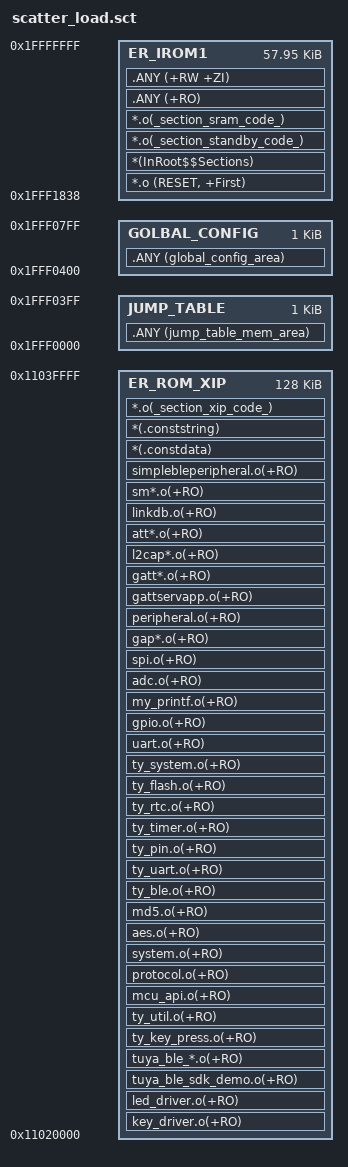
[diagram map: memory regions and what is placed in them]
; *************************************************************
; *** Scatter-Loading Description File generated by uVision ***
; *************************************************************

LR_IROM1 0x1fff1838 0x0E7C8 {  ; load region size_region
 ER_IROM1 0x1fff1838 0x0E7C8  {  ; load address = execution address
  *.o (RESET, +First)
  *(InRoot$$Sections)
  *.o(_section_standby_code_)
  *.o(_section_sram_code_)
  .ANY (+RO)  
  .ANY (+RW +ZI)
 }
;  ER_IROM2 0x1fffc000 0x04000  {  ; load address = execution address
;  rf_phy_driver.o(i.rf_phy_dtm*)
;  rf_phy_driver.o(i.rf_phy_direct_*)
; }
}
LR_ROM_JT_GC  0x1fff0000 0x00800 {
  JUMP_TABLE 0x1fff0000 0x00400  {
   .ANY (jump_table_mem_area) 
	
  }
  GOLBAL_CONFIG 0x1fff0400 0x00400  {
   .ANY (global_config_area) 
	
  }  
 } 
LR_ROM_XIP  0x11020000 0x020000 {
  ER_ROM_XIP 0x11020000 0x020000  {  ; load address = execution address

   key_driver.o(+RO)
   led_driver.o(+RO)
   tuya_ble_sdk_demo.o(+RO)
   tuya_ble_*.o(+RO)
   ;ty_oled.o(+RO)
   ty_key_press.o(+RO)
   ty_util.o(+RO)
   mcu_api.o(+RO)
   protocol.o(+RO)
   system.o(+RO)
   aes.o(+RO)
   md5.o(+RO)
   ;sha1.o(+RO)
   ;sha256.o(+RO)
   ;elog.o(+RO)
   ;elog_async.o(+RO)
   ;elog_buf.o(+RO)
   ;elog_util.o(+RO)
   ;elog_port.o(+RO)
   ty_ble.o(+RO)
   ty_uart.o(+RO)
   ;ty_i2c.o(+RO)
   ;ty_spi.o(+RO)
   ;ty_adc.o(+RO)
   ;ty_pwm.o(+RO)
   ty_pin.o(+RO)
   ty_timer.o(+RO)
   ty_rtc.o(+RO)
   ty_flash.o(+RO)
   ty_system.o(+RO)
   ;main.o(+RO)
   uart.o(+RO)
   ;clock.o(+RO)
   gpio.o(+RO)
   ;timer.o(+RO)
   ;pwrmgr.o(+RO)
   my_printf.o(+RO)
   ;key.o(+RO)
   ;pwm.o(+RO)
   ;osal_snv.o(+RO)
   ;flash.o(+RO)
   adc.o(+RO)
   ;i2c.o(+RO)
   spi.o(+RO)
   ;central.o(+RO)
   gap*.o(+RO)
   peripheral.o(+RO)
   gattservapp.o(+RO)
   ;tuya_ble_service.o(+RO)
   ;jump_table.o(+RO)
   gatt*.o(+RO)
   l2cap*.o(+RO)
   att*.o(+RO)
   linkdb.o(+RO)
   sm*.o(+RO)
   ;OSAL_SimpleBLEPeripheral.o(+RO)
   simplebleperipheral.o(+RO)
   ;SimpleBLEPeripheral_Main.o(+RO)
   *(.constdata)
   *(.conststring)
   *.o(_section_xip_code_)
  }
 }  



